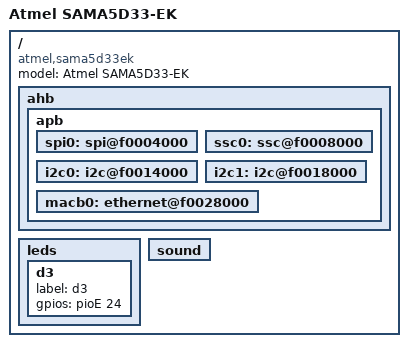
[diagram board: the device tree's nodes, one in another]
/*
 * sama5d33ek_revc_pda7.dts - Device Tree file for SAMA5D33-EK with rev.C MB + PDA7" LCD
 *
 *  Copyright (C) 2013 Atmel,
 *                2013 Ludovic Desroches <ludovic.desroches@atmel.com>
 *
 * Licensed under GPLv2 or later.
 */
/dts-v1/;
#include "sama5d33.dtsi"
#include "sama5d3xmb.dtsi"
#include "sama5d3xmb_revc_audio.dtsi"
#include "sama5d3xdm_pda7.dtsi"

/ {
	model = "Atmel SAMA5D33-EK";
	compatible = "atmel,sama5d33ek", "pda,tm70xx", "atmel,sama5d3xmb", "atmel,sama5d3xcm", "atmel,sama5d33", "atmel,sama5d3", "atmel,sama5";

	ahb {
		apb {
			spi0: spi@f0004000 {
				status = "okay";
			};

			ssc0: ssc@f0008000 {
				status = "okay";
			};

			i2c0: i2c@f0014000 {
				status = "okay";
			};

			i2c1: i2c@f0018000 {
				status = "okay";
			};

			macb0: ethernet@f0028000 {
				status = "okay";
			};
		};
	};

	leds {
		d3 {
			label = "d3";
			gpios = <&pioE 24 GPIO_ACTIVE_HIGH>;
		};
	};

	sound {
		status = "okay";
	};
};
